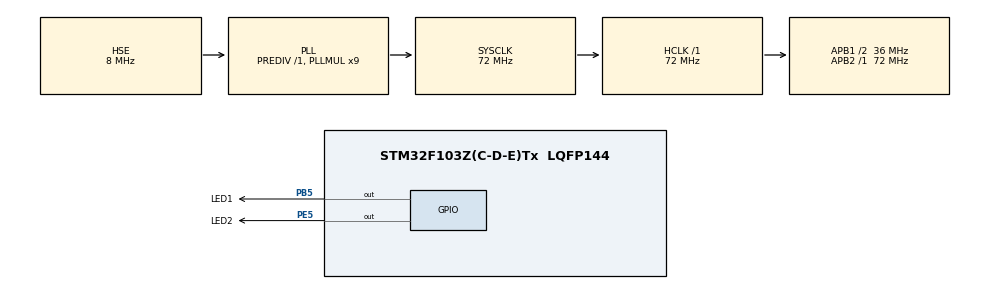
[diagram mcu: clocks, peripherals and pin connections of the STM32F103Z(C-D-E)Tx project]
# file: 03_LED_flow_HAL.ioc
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Mcu.Family=STM32F1
Mcu.Name=STM32F103Z(C-D-E)Tx
Mcu.Package=LQFP144
NVIC.PriorityGroup=NVIC_PRIORITYGROUP_4
OSC_IN.Mode=HSE-External-Oscillator
OSC_IN.Signal=RCC_OSC_IN
OSC_OUT.Mode=HSE-External-Oscillator
OSC_OUT.Signal=RCC_OSC_OUT
PA13.Mode=Serial_Wire
PA13.Signal=SYS_JTMS-SWDIO
PA14.Mode=Serial_Wire
PA14.Signal=SYS_JTCK-SWCLK
PB5.GPIO_Label=LED1
PB5.PinState=GPIO_PIN_SET
PB5.Signal=GPIO_Output
PC14-OSC32_IN.Mode=LSE-External-Oscillator
PC14-OSC32_IN.Signal=RCC_OSC32_IN
PC15-OSC32_OUT.Mode=LSE-External-Oscillator
PC15-OSC32_OUT.Signal=RCC_OSC32_OUT
PE5.GPIO_Label=LED2
PE5.PinState=GPIO_PIN_SET
PE5.Signal=GPIO_Output
ProjectManager.HeapSize=0x200
ProjectManager.StackSize=0x400
ProjectManager.TargetToolchain=MDK-ARM V5.32
RCC.AHBFreq_Value=72000000
RCC.APB1CLKDivider=RCC_HCLK_DIV2
RCC.APB1Freq_Value=36000000
RCC.APB1TimFreq_Value=72000000
RCC.APB2Freq_Value=72000000
RCC.APB2TimFreq_Value=72000000
RCC.HCLKFreq_Value=72000000
RCC.PLLMUL=RCC_PLL_MUL9
RCC.PLLSourceVirtual=RCC_PLLSOURCE_HSE
RCC.SYSCLKFreq_VALUE=72000000
RCC.SYSCLKSource=RCC_SYSCLKSOURCE_PLLCLK
RCC.USBFreq_Value=72000000
board=custom

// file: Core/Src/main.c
/* USER CODE BEGIN Header */
/**
  ******************************************************************************
  * @file           : main.c
  * @brief          : Main program body
  ******************************************************************************
  * @attention
  *
  * Copyright (c) 2026 STMicroelectronics.
  * All rights reserved.
  *
  * This software is licensed under terms that can be found in the LICENSE file
  * in the root directory of this software component.
  * If no LICENSE file comes with this software, it is provided AS-IS.
  *
  ******************************************************************************
  */
/* USER CODE END Header */
#include "main.h"
#include "gpio.h"

/* USER CODE BEGIN Includes */

#include "../../../interface/inc/inf_led.h"  // 包含LED接口层头文件，提供inf_led_xxx()函数
/* USER CODE END Includes */

void SystemClock_Config(void);

int main(void)
{

  /* MCU Configuration--------------------------------------------------------*/

  /* Reset of all peripherals, Initializes the Flash interface and the Systick. */
  HAL_Init();

  /* Configure the system clock */
  SystemClock_Config();

  /* Initialize all configured peripherals */
  MX_GPIO_Init();
  /* USER CODE BEGIN 2 */
	// 初始化LED系统（内部已调用MX_GPIO_Init和关闭所有LED）
	// 为什么不需要传参数？因为inf_led_init()是全局初始化，会自动处理所有LED
	inf_led_init();

  /* USER CODE END 2 */

  /* Infinite loop */
  /* USER CODE BEGIN WHILE */
  while (1)
  {
    // ========== 流水灯效果：LED1 -> LED2 ==========
    //
    // 【为什么LED1用GPIOB，LED2用GPIOE？】
    // ---------------------------------------------------------------------------
    // 因为你的硬件连接是：
    //   - LED1连接在PB5（GPIOB端口的第5脚）
    //   - LED2连接在PE5（GPIOE端口的第5脚）
    //
    // 老师的代码：所有LED都在GPIOA，所以可以写死
    //   inf_led_open(LED1_Pin);  // 内部固定用GPIOA
    //
    // 我们的代码：需要明确指定端口和引脚
    //   inf_led_open(GPIOB, LED1_Pin);  // 点亮GPIOB上的LED1
    //   inf_led_open(GPIOE, LED2_Pin);  // 点亮GPIOE上的LED2

    // 第1步：点亮LED1（PB5）
    inf_led_open(GPIOB, LED1_Pin);  // PB5输出低电平，LED1亮
    HAL_Delay(500);                  // 延时500毫秒，保持亮状态
    inf_led_close(GPIOB, LED1_Pin);  // PB5输出高电平，LED1灭

    // 第2步：点亮LED2（PE5）
    inf_led_open(GPIOE, LED2_Pin);  // PE5输出低电平，LED2亮
    HAL_Delay(500);                  // 延时500毫秒，保持亮状态
    inf_led_close(GPIOE, LED2_Pin);  // PE5输出高电平，LED2灭

    // 循环回到第1步，形成流水灯效果：LED1亮灭 -> LED2亮灭 -> LED1亮灭...

    /* USER CODE END WHILE */
  }
}

void SystemClock_Config(void)
{
  RCC_OscInitTypeDef RCC_OscInitStruct = {0};
  RCC_ClkInitTypeDef RCC_ClkInitStruct = {0};

  /** Initializes the RCC Oscillators according to the specified parameters
  * in the RCC_OscInitTypeDef structure.
  */
  RCC_OscInitStruct.OscillatorType = RCC_OSCILLATORTYPE_HSE;
  RCC_OscInitStruct.HSEState = RCC_HSE_ON;
  RCC_OscInitStruct.HSEPredivValue = RCC_HSE_PREDIV_DIV1;
  RCC_OscInitStruct.HSIState = RCC_HSI_ON;
  RCC_OscInitStruct.PLL.PLLState = RCC_PLL_ON;
  RCC_OscInitStruct.PLL.PLLSource = RCC_PLLSOURCE_HSE;
  RCC_OscInitStruct.PLL.PLLMUL = RCC_PLL_MUL9;
  if (HAL_RCC_OscConfig(&RCC_OscInitStruct) != HAL_OK)
  {
    Error_Handler();
  }

  /** Initializes the CPU, AHB and APB buses clocks
  */
  RCC_ClkInitStruct.ClockType = RCC_CLOCKTYPE_HCLK|RCC_CLOCKTYPE_SYSCLK
                              |RCC_CLOCKTYPE_PCLK1|RCC_CLOCKTYPE_PCLK2;
  RCC_ClkInitStruct.SYSCLKSource = RCC_SYSCLKSOURCE_PLLCLK;
  RCC_ClkInitStruct.AHBCLKDivider = RCC_SYSCLK_DIV1;
  RCC_ClkInitStruct.APB1CLKDivider = RCC_HCLK_DIV2;
  RCC_ClkInitStruct.APB2CLKDivider = RCC_HCLK_DIV1;

  if (HAL_RCC_ClockConfig(&RCC_ClkInitStruct, FLASH_LATENCY_2) != HAL_OK)
  {
    Error_Handler();
  }
}

void Error_Handler(void)
{
  __disable_irq();
  while (1)
  {
  }
}
